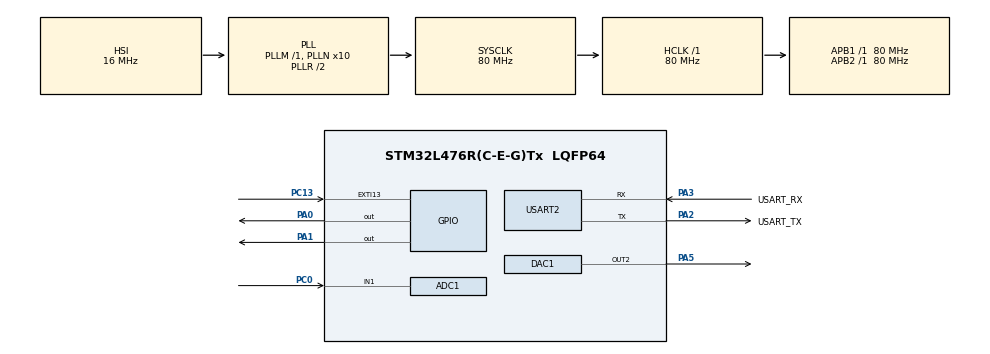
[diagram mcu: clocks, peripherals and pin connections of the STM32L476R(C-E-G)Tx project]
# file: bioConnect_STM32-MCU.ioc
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ADC1.Channel-2\#ChannelRegularConversion=ADC_CHANNEL_1
ADC1.ClockPrescaler=ADC_CLOCK_ASYNC_DIV16
ADC1.ContinuousConvMode=DISABLE
ADC1.NbrOfConversionFlag=1
ADC1.OffsetNumber-2\#ChannelRegularConversion=ADC_OFFSET_NONE
ADC1.OversamplingMode=ENABLE
ADC1.Rank-2\#ChannelRegularConversion=1
ADC1.Ratio=ADC_OVERSAMPLING_RATIO_16
ADC1.RightBitShift=ADC_RIGHTBITSHIFT_4
ADC1.SamplingTime-2\#ChannelRegularConversion=ADC_SAMPLETIME_12CYCLES_5
ADC1.master=1
DAC1.DAC_Channel-DAC_OUT2=DAC_CHANNEL_2
Mcu.Family=STM32L4
Mcu.Name=STM32L476R(C-E-G)Tx
Mcu.Package=LQFP64
NVIC.ADC1_2_IRQn=true\:0\:0\:false\:false\:true\:true\:true\:true
NVIC.EXTI15_10_IRQn=true\:0\:0\:false\:false\:true\:true\:true\:true
NVIC.PriorityGroup=NVIC_PRIORITYGROUP_4
NVIC.TIM6_DAC_IRQn=true\:0\:0\:false\:false\:true\:true\:true\:true
PA0.Signal=GPIO_Output
PA1.Signal=GPIO_Output
PA13\ (JTMS-SWDIO).GPIO_Label=TMS
PA13\ (JTMS-SWDIO).Mode=Serial_Wire
PA13\ (JTMS-SWDIO).Signal=SYS_JTMS-SWDIO
PA14\ (JTCK-SWCLK).GPIO_Label=TCK
PA14\ (JTCK-SWCLK).Mode=Serial_Wire
PA14\ (JTCK-SWCLK).Signal=SYS_JTCK-SWCLK
PA2.GPIO_Label=USART_TX
PA2.GPIO_Mode=GPIO_MODE_AF_PP
PA2.GPIO_PuPd=GPIO_NOPULL
PA2.GPIO_Speed=GPIO_SPEED_FREQ_VERY_HIGH
PA2.Mode=Asynchronous
PA2.Signal=USART2_TX
PA3.GPIO_Label=USART_RX
PA3.GPIO_Mode=GPIO_MODE_AF_PP
PA3.GPIO_PuPd=GPIO_NOPULL
PA3.GPIO_Speed=GPIO_SPEED_FREQ_VERY_HIGH
PA3.Mode=Asynchronous
PA3.Signal=USART2_RX
PA5.Signal=COMP_DAC12_group
PB3\ (JTDO-TRACESWO).GPIO_Label=SWO
PB3\ (JTDO-TRACESWO).Signal=SYS_JTDO-SWO
PC0.Signal=ADCx_IN1
PC13.Signal=GPXTI13
PC14-OSC32_IN\ (PC14).Mode=LSE-External-Oscillator
PC14-OSC32_IN\ (PC14).Signal=RCC_OSC32_IN
PC15-OSC32_OUT\ (PC15).Mode=LSE-External-Oscillator
PC15-OSC32_OUT\ (PC15).Signal=RCC_OSC32_OUT
PH0-OSC_IN\ (PH0).Signal=RCC_OSC_IN
PH1-OSC_OUT\ (PH1).Signal=RCC_OSC_OUT
ProjectManager.HeapSize=0x200
ProjectManager.StackSize=0x400
ProjectManager.TargetToolchain=STM32CubeIDE
RCC.ADCFreq_Value=64000000
RCC.AHBFreq_Value=80000000
RCC.APB1Freq_Value=80000000
RCC.APB1TimFreq_Value=80000000
RCC.APB2Freq_Value=80000000
RCC.APB2TimFreq_Value=80000000
RCC.CortexFreq_Value=80000000
RCC.HCLKFreq_Value=80000000
RCC.HSE_VALUE=8000000
RCC.HSI_VALUE=16000000
RCC.MSI_VALUE=4000000
RCC.PLLN=10
RCC.PLLSourceVirtual=RCC_PLLSOURCE_HSI
RCC.PREFETCH_ENABLE=1
RCC.SYSCLKFreq_VALUE=80000000
RCC.SYSCLKSource=RCC_SYSCLKSOURCE_PLLCLK
RCC.USBFreq_Value=64000000
RCC.VCOOutputFreq_Value=160000000
SH.ADCx_IN1.0=ADC1_IN1,IN1-Single-Ended
SH.COMP_DAC12_group.0=DAC1_OUT2,DAC_OUT2
TIM6.Period=99
TIM6.Prescaler=7999
USART2.VirtualMode-Asynchronous=VM_ASYNC
VP_TIM6_VS_ClockSourceINT.Mode=Enable_Timer
board=NUCLEO-L476RG

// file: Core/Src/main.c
/* USER CODE BEGIN Header */
/**
  ******************************************************************************
  * @file           : main.c
  * @brief          : Main program body
  ******************************************************************************
  * @attention
  *
  * Copyright (c) 2024 STMicroelectronics.
  * All rights reserved.
  *
  * This software is licensed under terms that can be found in the LICENSE file
  * in the root directory of this software component.
  * If no LICENSE file comes with this software, it is provided AS-IS.
  *
  ******************************************************************************
  */
/* USER CODE END Header */
#include "main.h"

/* USER CODE BEGIN Includes */
#include "string.h"
#include <stdio.h>
#include <stdbool.h>
//#include "stm3214xx_ll_tim.h"
/* USER CODE END Includes */

/* USER CODE BEGIN PD */
#define ADC_TIMEOUT 1000
#define UART_TIMEOUT 1000
/* USER CODE END PD */

/* USER CODE BEGIN PM */
//volatile - make this variables changable during interrupts
//variable to know which LED should work 0 - Ready (No LED), 1 - Red, 2 - IR
volatile uint8_t measurement_state = 0;

//variable which check that data is complite: 0 - not complite, 1 - complite
static volatile uint8_t data_ready = 0;

//variable for remember data values
//volatile uint32_t val_red = 0;
//volatile uint32_t val_ir = 0;
static volatile uint32_t val_dark = 0;

// Transfer to buffer to collect measured data
//const int16_t N = 64; // number of elements in buffer
#define N 64
// Red BUFFER:
static volatile uint32_t buffer_Red[N]; // buffer memory
static volatile int16_t tail_Red = 0; // index pointing to next empty storage space in buffer
static volatile int16_t head_Red = 0; // index pointing to oldest element added

// IR BUFFER:
static volatile uint32_t buffer_IR[N]; // buffer memory
static volatile int16_t tail_IR = 0; // index pointing to next empty storage space in buffer
static volatile int16_t head_IR = 0; // index pointing to oldest element added

/* USER CODE END PM */

ADC_HandleTypeDef hadc1;

DAC_HandleTypeDef hdac1;

TIM_HandleTypeDef htim6;

UART_HandleTypeDef huart2;

void SystemClock_Config(void);
static void MX_GPIO_Init(void);
static void MX_USART2_UART_Init(void);
static void MX_ADC1_Init(void);
static void MX_DAC1_Init(void);
static void MX_TIM6_Init(void);
/* USER CODE BEGIN PFP */

void Measure_interrupt(void);

/* USER CODE END PFP */

/* USER CODE BEGIN 0 */
void Enqueue_Red(uint32_t val)
{
	buffer_Red[tail_Red] = val;
	tail_Red = (tail_Red + 1) % N;
}

void Enqueue_IR(uint32_t val)
{
	buffer_IR[tail_IR] = val;
	tail_IR = (tail_IR + 1) % N;
}

uint32_t Dequeue_Red(void)
{
	uint32_t val = 0;
	if (head_Red != tail_Red)
	{
		val = buffer_Red[head_Red];
		head_Red = (head_Red + 1) % N;
	}
	return val;
}

uint32_t Dequeue_IR(void)
{
	uint32_t val = 0;
	if (head_IR != tail_IR)
	{
		val = buffer_IR[head_IR];
		head_IR = (head_IR + 1) % N;
	}
	return val;
}

bool isEmpty_Red(void)
{
return (tail_Red == head_Red);
}

bool isEmpty_IR(void)
{
return (tail_IR == head_IR);
}
/* USER CODE END 0 */

int main(void)
{

  /* USER CODE BEGIN 1 */
  uint32_t value_dac=0;
  char msg[100] = "Hello, World"; //note that 100 chars is the maximum length of the message
  /* USER CODE END 1 */

  /* MCU Configuration--------------------------------------------------------*/

  /* Reset of all peripherals, Initializes the Flash interface and the Systick. */
  HAL_Init();

  /* Configure the system clock */
  SystemClock_Config();

  /* Initialize all configured peripherals */
  MX_GPIO_Init();
  MX_USART2_UART_Init();
  MX_ADC1_Init();
  MX_DAC1_Init();
  MX_TIM6_Init();
  /* USER CODE BEGIN 2 */
  HAL_DAC_Start(&hdac1,DAC_CHANNEL_2);
  HAL_ADCEx_Calibration_Start(&hadc1, ADC_SINGLE_ENDED);
  HAL_UART_Transmit(&huart2, (uint8_t*)msg, strlen(msg), 0xFFFF); //print a hello world to begin the program

  //HAL_TIM_Base_Start_IT(&htim3); //transfer timer from Delay to interruption

    // Create a correct ADC interruption implementation
    __HAL_ADC_CLEAR_FLAG(&hadc1, (ADC_FLAG_EOC | ADC_FLAG_EOS | ADC_FLAG_OVR));

    HAL_NVIC_SetPriority(ADC1_2_IRQn, 0, 0);
    HAL_NVIC_EnableIRQ(ADC1_2_IRQn);

    uint32_t last_update = 0;
//    HAL_TIM_Base_Start_IT(&htim6); // Enable TIM6 as in Ex5.2
  /* USER CODE END 2 */

  /* Infinite loop */
  /* USER CODE BEGIN WHILE */

  /* WHILE_WHILE_WHILE_WHILE_WHILE_WHILE_WHILE_WHILE_WHILE_WHILE_WHILE_WHILE_WHILE_WHILE_WHILE_*WHILE_WHILE_WHILE_*/

  while (1)
  {
	  //---ADC---
	  //The ADC returns a 12bit value in unsigned integer format.
	  //The input range of the ADC is 0V < Vin < Vref+. Vref+ is connected to VDD (3.3V)
	  //Therefore, the ADC value 0x000 corresponds to 0V input voltage, and the ADC value 0xFFF corresponds to 3.3V input voltage.

	  //HAL_ADC_Start_IT(&hadc1); //instead of polling use interrupts HAL_ADC_Start(&hadc1); it don't waised time

//	  if (data_ready == 1)
//	  {
//		  data_ready = 0; //(НАДО ЧЕКНУТЬ ЧТО ЕСЛИ ТУТ ПРЕРЫВАНИЯ ВОЗНИКНУТ)
//		  //---ADC raw value transmission over UART---
//		  	  //the values are formatted as long unsigned integer (%lu) and \r\n are used for carriage return (start at leftmost position) and new line.
//		  sprintf(msg, "%lu,%lu\r\n",val_red, val_ir);
//		  HAL_UART_Transmit(&huart2, (uint8_t*)msg, strlen(msg), UART_TIMEOUT);
//
//	  }

	  if (!isEmpty_IR())
	  {
		  uint32_t val_red = Dequeue_Red();
		  uint32_t val_ir = Dequeue_IR();
		  sprintf(msg, "%lu,%lu\r\n",val_red, val_ir);
		  HAL_UART_Transmit(&huart2, (uint8_t*)msg, strlen(msg), UART_TIMEOUT);

	  }

	  if (HAL_GetTick() - last_update >= 10 && measurement_state == 0)
	  {
		  last_update = HAL_GetTick();
		  measurement_state = 3;
		  Measure_interrupt();
	  }
	  //---DAC (for testing purpose only)---
	  //The code below generates a sawtooth waveform and outputs in with the DAC on LD2 and Pin D13
	  //If you want to read back the waveform with the ADC, connect Pin D13 (DAC OUT) to A5 (ADC IN) together on your Nucleo Board.
	  //The two values should then be similar.

//	  HAL_DAC_SetValue(&hdac1, DAC_CHANNEL_2, DAC_ALIGN_12B_R, value_dac);
//	  value_dac++;
//	  if(value_dac>4095) {
//	    value_dac=0;
//      }

      //---Wait for systick---
      //HAL_Delay(10); //wait for the next systick (1ms) - this limits the sampling rate to 1kHz. We use "0" because the function adds +1.

    /* USER CODE END WHILE */

    /* USER CODE BEGIN 3 */
//		int updateevent = LL_TIM_IsActiveFlag_UPDATE(TIM6);
//		if(updateevent)
//		{
//		LL_TIM_ClearFlag_UPDATE(TIM6);
//		measurement_state = 1;
//		Measure_interrupt();
//		}

  }
  /* USER CODE END 3 */
}

void SystemClock_Config(void)
{
  RCC_OscInitTypeDef RCC_OscInitStruct = {0};
  RCC_ClkInitTypeDef RCC_ClkInitStruct = {0};

  /** Configure the main internal regulator output voltage
  */
  if (HAL_PWREx_ControlVoltageScaling(PWR_REGULATOR_VOLTAGE_SCALE1) != HAL_OK)
  {
    Error_Handler();
  }

  /** Initializes the RCC Oscillators according to the specified parameters
  * in the RCC_OscInitTypeDef structure.
  */
  RCC_OscInitStruct.OscillatorType = RCC_OSCILLATORTYPE_HSI;
  RCC_OscInitStruct.HSIState = RCC_HSI_ON;
  RCC_OscInitStruct.HSICalibrationValue = RCC_HSICALIBRATION_DEFAULT;
  RCC_OscInitStruct.PLL.PLLState = RCC_PLL_ON;
  RCC_OscInitStruct.PLL.PLLSource = RCC_PLLSOURCE_HSI;
  RCC_OscInitStruct.PLL.PLLM = 1;
  RCC_OscInitStruct.PLL.PLLN = 10;
  RCC_OscInitStruct.PLL.PLLP = RCC_PLLP_DIV7;
  RCC_OscInitStruct.PLL.PLLQ = RCC_PLLQ_DIV2;
  RCC_OscInitStruct.PLL.PLLR = RCC_PLLR_DIV2;
  if (HAL_RCC_OscConfig(&RCC_OscInitStruct) != HAL_OK)
  {
    Error_Handler();
  }

  /** Initializes the CPU, AHB and APB buses clocks
  */
  RCC_ClkInitStruct.ClockType = RCC_CLOCKTYPE_HCLK|RCC_CLOCKTYPE_SYSCLK
                              |RCC_CLOCKTYPE_PCLK1|RCC_CLOCKTYPE_PCLK2;
  RCC_ClkInitStruct.SYSCLKSource = RCC_SYSCLKSOURCE_PLLCLK;
  RCC_ClkInitStruct.AHBCLKDivider = RCC_SYSCLK_DIV1;
  RCC_ClkInitStruct.APB1CLKDivider = RCC_HCLK_DIV1;
  RCC_ClkInitStruct.APB2CLKDivider = RCC_HCLK_DIV1;

  if (HAL_RCC_ClockConfig(&RCC_ClkInitStruct, FLASH_LATENCY_4) != HAL_OK)
  {
    Error_Handler();
  }
}

static void MX_ADC1_Init(void)
{

  ADC_MultiModeTypeDef multimode = {0};
  ADC_ChannelConfTypeDef sConfig = {0};

  /** Common config
  */
  hadc1.Instance = ADC1;
  hadc1.Init.ClockPrescaler = ADC_CLOCK_ASYNC_DIV256;
  hadc1.Init.Resolution = ADC_RESOLUTION_12B;
  hadc1.Init.DataAlign = ADC_DATAALIGN_RIGHT;
  hadc1.Init.ScanConvMode = ADC_SCAN_DISABLE;
  hadc1.Init.EOCSelection = ADC_EOC_SINGLE_CONV;
  hadc1.Init.LowPowerAutoWait = DISABLE;
  hadc1.Init.ContinuousConvMode = DISABLE;
  hadc1.Init.NbrOfConversion = 1;
  hadc1.Init.DiscontinuousConvMode = DISABLE;
  hadc1.Init.ExternalTrigConv = ADC_SOFTWARE_START;
  hadc1.Init.ExternalTrigConvEdge = ADC_EXTERNALTRIGCONVEDGE_NONE;
  hadc1.Init.DMAContinuousRequests = DISABLE;
  hadc1.Init.Overrun = ADC_OVR_DATA_PRESERVED;
  hadc1.Init.OversamplingMode = DISABLE;
  if (HAL_ADC_Init(&hadc1) != HAL_OK)
  {
    Error_Handler();
  }

  /** Configure the ADC multi-mode
  */
  multimode.Mode = ADC_MODE_INDEPENDENT;
  if (HAL_ADCEx_MultiModeConfigChannel(&hadc1, &multimode) != HAL_OK)
  {
    Error_Handler();
  }

  /** Configure Regular Channel
  */
  sConfig.Channel = ADC_CHANNEL_1;
  sConfig.Rank = ADC_REGULAR_RANK_1;
  sConfig.SamplingTime = ADC_SAMPLETIME_12CYCLES_5;
  sConfig.SingleDiff = ADC_SINGLE_ENDED;
  sConfig.OffsetNumber = ADC_OFFSET_NONE;
  sConfig.Offset = 0;
  if (HAL_ADC_ConfigChannel(&hadc1, &sConfig) != HAL_OK)
  {
    Error_Handler();
  }

}

static void MX_DAC1_Init(void)
{

  DAC_ChannelConfTypeDef sConfig = {0};

  /** DAC Initialization
  */
  hdac1.Instance = DAC1;
  if (HAL_DAC_Init(&hdac1) != HAL_OK)
  {
    Error_Handler();
  }

  /** DAC channel OUT2 config
  */
  sConfig.DAC_SampleAndHold = DAC_SAMPLEANDHOLD_DISABLE;
  sConfig.DAC_Trigger = DAC_TRIGGER_NONE;
  sConfig.DAC_OutputBuffer = DAC_OUTPUTBUFFER_ENABLE;
  sConfig.DAC_ConnectOnChipPeripheral = DAC_CHIPCONNECT_DISABLE;
  sConfig.DAC_UserTrimming = DAC_TRIMMING_FACTORY;
  if (HAL_DAC_ConfigChannel(&hdac1, &sConfig, DAC_CHANNEL_2) != HAL_OK)
  {
    Error_Handler();
  }

}

static void MX_TIM6_Init(void)
{

  TIM_MasterConfigTypeDef sMasterConfig = {0};

  htim6.Instance = TIM6;
  htim6.Init.Prescaler = 7999;
  htim6.Init.CounterMode = TIM_COUNTERMODE_UP;
  htim6.Init.Period = 99;
  htim6.Init.AutoReloadPreload = TIM_AUTORELOAD_PRELOAD_DISABLE;
  if (HAL_TIM_Base_Init(&htim6) != HAL_OK)
  {
    Error_Handler();
  }
  sMasterConfig.MasterOutputTrigger = TIM_TRGO_RESET;
  sMasterConfig.MasterSlaveMode = TIM_MASTERSLAVEMODE_DISABLE;
  if (HAL_TIMEx_MasterConfigSynchronization(&htim6, &sMasterConfig) != HAL_OK)
  {
    Error_Handler();
  }

}

static void MX_USART2_UART_Init(void)
{

  huart2.Instance = USART2;
  huart2.Init.BaudRate = 115200;
  huart2.Init.WordLength = UART_WORDLENGTH_8B;
  huart2.Init.StopBits = UART_STOPBITS_1;
  huart2.Init.Parity = UART_PARITY_NONE;
  huart2.Init.Mode = UART_MODE_TX_RX;
  huart2.Init.HwFlowCtl = UART_HWCONTROL_NONE;
  huart2.Init.OverSampling = UART_OVERSAMPLING_16;
  huart2.Init.OneBitSampling = UART_ONE_BIT_SAMPLE_DISABLE;
  huart2.AdvancedInit.AdvFeatureInit = UART_ADVFEATURE_NO_INIT;
  if (HAL_UART_Init(&huart2) != HAL_OK)
  {
    Error_Handler();
  }

}

static void MX_GPIO_Init(void)
{
  GPIO_InitTypeDef GPIO_InitStruct = {0};

  /* GPIO Ports Clock Enable */
  __HAL_RCC_GPIOC_CLK_ENABLE();
  __HAL_RCC_GPIOH_CLK_ENABLE();
  __HAL_RCC_GPIOA_CLK_ENABLE();
  __HAL_RCC_GPIOB_CLK_ENABLE();

  /*Configure GPIO pin Output Level */
  HAL_GPIO_WritePin(GPIOA, GPIO_PIN_0|GPIO_PIN_1, GPIO_PIN_RESET);

  /*Configure GPIO pin : B1_Pin */
  GPIO_InitStruct.Pin = B1_Pin;
  GPIO_InitStruct.Mode = GPIO_MODE_IT_FALLING;
  GPIO_InitStruct.Pull = GPIO_NOPULL;
  HAL_GPIO_Init(B1_GPIO_Port, &GPIO_InitStruct);

  /*Configure GPIO pins : PA0 PA1 */
  GPIO_InitStruct.Pin = GPIO_PIN_0|GPIO_PIN_1;
  GPIO_InitStruct.Mode = GPIO_MODE_OUTPUT_PP;
  GPIO_InitStruct.Pull = GPIO_NOPULL;
  GPIO_InitStruct.Speed = GPIO_SPEED_FREQ_LOW;
  HAL_GPIO_Init(GPIOA, &GPIO_InitStruct);

}

/* USER CODE BEGIN 4 */
/* MY_PERIPHERALS!__MY_PERIPHERALS!__MY_PERIPHERALS!__MY_PERIPHERALS!__MY_PERIPHERALS!__MY_PERIPHERALS!__MY_PERIPHERALS!__*/

void HAL_ADC_ConvCpltCallback (ADC_HandleTypeDef* hadc)
{
	uint32_t raw_val = HAL_ADC_GetValue(&hadc1);
	uint32_t val = 0;
	if (measurement_state == 3)
	{
		val_dark = raw_val;
		measurement_state = 1;
		Measure_interrupt();
	}
	else if (measurement_state == 1)
	{
		//val_red = (raw_val > val_dark) ? (raw_val - val_dark) : 0;
		val = (raw_val > val_dark) ? (raw_val - val_dark) : 0;
		Enqueue_Red(val);
		measurement_state = 2;
		Measure_interrupt();
	}

	else if (measurement_state == 2)
	{
		//val_ir = (raw_val > val_dark) ? (raw_val - val_dark) : 0;
		val = (raw_val > val_dark) ? (raw_val - val_dark) : 0;
		Enqueue_IR(val);
		//data_ready = 1;
		measurement_state = 0;
		Measure_interrupt();

	}
}

void Measure_interrupt(void)
{
	if (measurement_state == 3)
	{
		HAL_ADC_Start_IT(&hadc1);
	}
	else if (measurement_state == 1)
	{
		HAL_GPIO_WritePin(GPIOA, GPIO_PIN_0, 1); //Turn ON RED
		HAL_ADC_Start_IT(&hadc1);
	}
	else if (measurement_state == 2)
	{
		HAL_GPIO_WritePin(GPIOA, GPIO_PIN_0, 0); //Turn OFF RED
		HAL_GPIO_WritePin(GPIOA, GPIO_PIN_1, 1); //Turn ON IR
		HAL_ADC_Start_IT(&hadc1);
	}
	else if (measurement_state == 0)
	{
		HAL_GPIO_WritePin(GPIOA, GPIO_PIN_0|GPIO_PIN_1, 0); //Turn OFF both LED
	}
	}

//void HAL_TIM_PeriodElapsedCallback(TIM_HandleTypeDef *htim)
//{
//	if (htim->Instance == TIM3)
//	{
//		if (measurement_state == 0)
//		{
//			measurement_state = 1;
//			Measure_interrupt();
//		}
//	}
//}

/* USER CODE END 4 */

void Error_Handler(void)
{
  __disable_irq();
  while (1)
  {
  }
}
